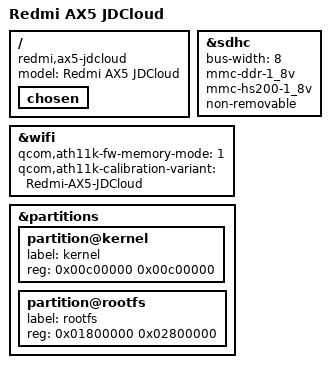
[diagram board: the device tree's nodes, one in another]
// SPDX-License-Identifier: GPL-2.0-or-later OR MIT

/dts-v1/;

#include "ipq6000-xiaomi.dtsi"

/ {
	model = "Redmi AX5 JDCloud";
	compatible = "redmi,ax5-jdcloud", "qcom,ipq6018";

	chosen {
		/delete-property/ bootargs-append;
	};
};

&sdhc {
	status = "okay";

	bus-width = <8>;
	mmc-ddr-1_8v;
	mmc-hs200-1_8v;
	non-removable;
};

&wifi {
	status = "okay";
	qcom,ath11k-fw-memory-mode = <1>;
	qcom,ath11k-calibration-variant = "Redmi-AX5-JDCloud";
};
&partitions {
	/* 这里的节点名称需要和 ipq6000-xiaomi.dtsi 里的完全一致 */
	partition@kernel {
		label = "kernel";
		reg = <0x00c00000 0x00c00000>; /* 起始偏移保持原样，大小改为 12MB (0x00c00000) */
	};

	partition@rootfs {
		label = "rootfs";
		/* ！！！致命警告 ！！！ */
		/* rootfs 的起始地址（第一参数）必须顺延紧接 kernel 的结束地址 */
		/* 由于增加了 6MB，起始地址要向后推移 0x00600000，且 rootfs 的大小（第二参数）必须减少 0x00600000 */
		reg = <0x01800000 0x02800000>; 
	};
};
